# S32K118_M0P register map
Vendor: NXP Semiconductors; File version: 1.1
CPU: CM0PLUS r0p0, little endian, MPU, FPU, VTOR, 4 interrupt priority bits
Registers are 32-bit, read-write, reset 0x0 unless marked. A register's access mark holds for its fields unless they carry their own. Offsets are from the block's base; [hi:lo] are bit positions; {n}, {i} and the like mark numbered series; 'fields as' and 'values as' point back to an identical list.

## TRGMUX
Base 0x40063000
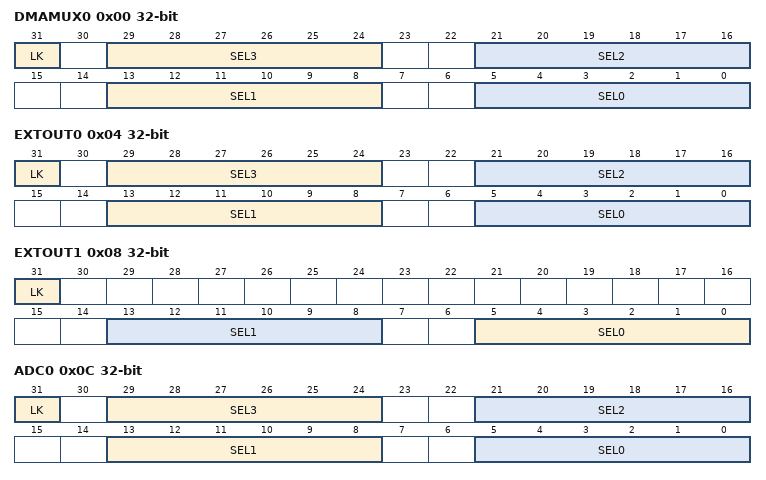
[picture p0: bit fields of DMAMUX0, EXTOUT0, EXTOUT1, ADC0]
0x00 DMAMUX0 — TRGMUX DMAMUX0 Register
  [31] LK — TRGMUX register lock.
    0=UNLOCKED (Register can be written.); 1=LOCKED (Register cannot be written until the next system Reset.)
  [8n+5:8n] SEL{n} (n=0..3) — Trigger MUX Input {n} Source Select
0x04 EXTOUT0 — TRGMUX EXTOUT0 Register
  fields as DMAMUX0
0x08 EXTOUT1 — TRGMUX EXTOUT1 Register
  [31] LK — TRGMUX register lock.
    values as DMAMUX0.LK
  [13:8] SEL1 — Trigger MUX Input 1 Source Select
  [5:0] SEL0 — Trigger MUX Input 0 Source Select
0x0C ADC0 — TRGMUX ADC0 Register
  fields as DMAMUX0
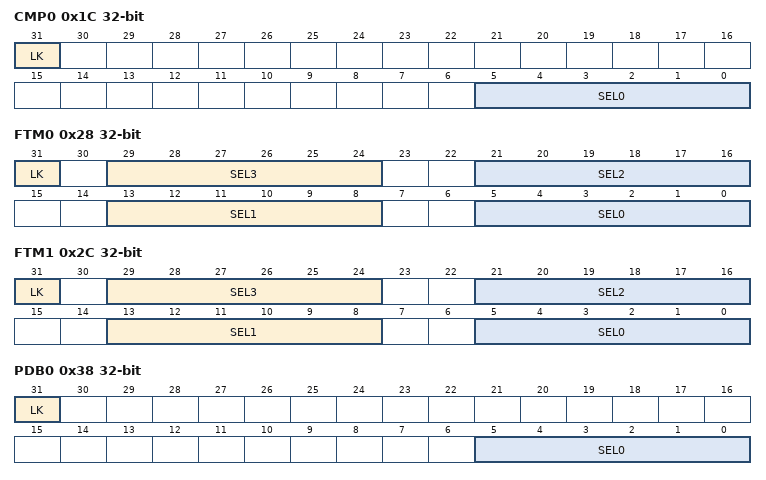
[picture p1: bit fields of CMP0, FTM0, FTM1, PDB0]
0x1C CMP0 — TRGMUX CMP0 Register
  [31] LK — TRGMUX register lock.
    values as DMAMUX0.LK
  [5:0] SEL0 — Trigger MUX Input 0 Source Select
0x28 FTM0 — TRGMUX FTM0 Register
  fields as DMAMUX0
0x2C FTM1 — TRGMUX FTM1 Register
  fields as DMAMUX0
0x38 PDB0 — TRGMUX PDB0 Register
  fields as CMP0
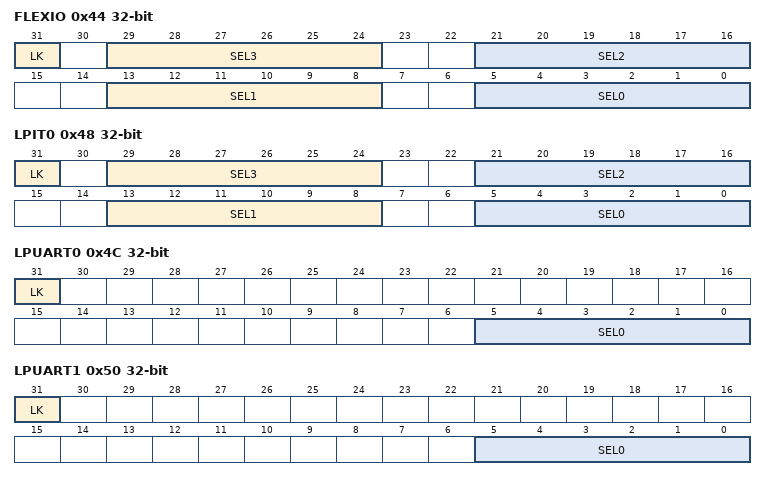
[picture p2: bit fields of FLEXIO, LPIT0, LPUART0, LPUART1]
0x44 FLEXIO — TRGMUX FLEXIO Register
  fields as DMAMUX0
0x48 LPIT0 — TRGMUX LPIT0 Register
  fields as DMAMUX0
0x4C LPUART0 — TRGMUX LPUART0 Register
  fields as CMP0
0x50 LPUART1 — TRGMUX LPUART1 Register
  fields as CMP0
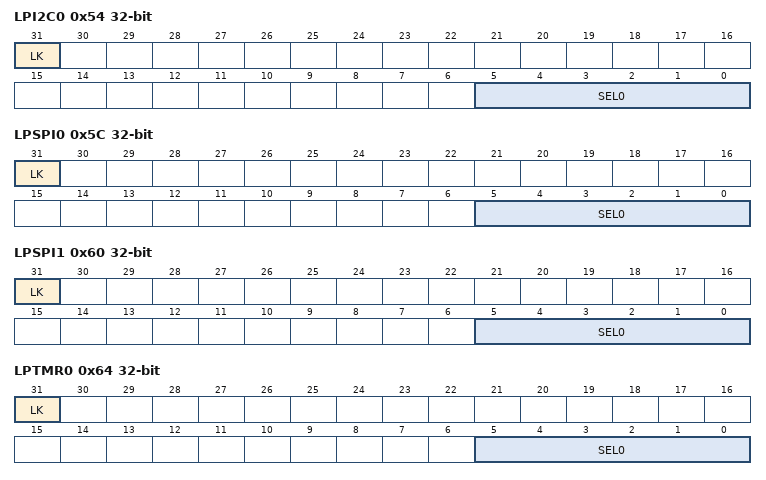
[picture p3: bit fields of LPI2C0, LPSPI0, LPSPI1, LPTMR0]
0x54 LPI2C0 — TRGMUX LPI2C0 Register
  fields as CMP0
0x5C LPSPI0 — TRGMUX LPSPI0 Register
  fields as CMP0
0x60 LPSPI1 — TRGMUX LPSPI1 Register
  fields as CMP0
0x64 LPTMR0 — TRGMUX LPTMR0 Register
  fields as CMP0

## PCC
Base 0x40065000
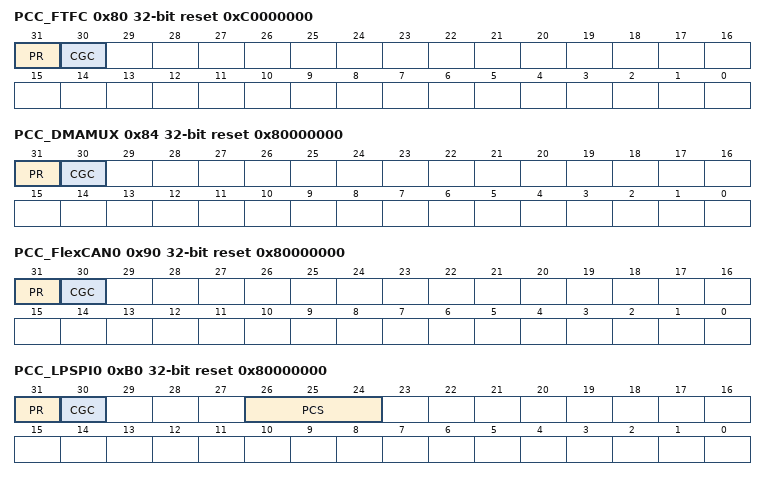
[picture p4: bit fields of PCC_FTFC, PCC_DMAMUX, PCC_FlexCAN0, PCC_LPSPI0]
0x80 PCC_FTFC reset 0xC0000000
  [31] PR ro — Present
    0=NOT_PRESENT (Peripheral is not present.); 1=PRESENT (Peripheral is present.)
  [30] CGC — Clock Gate Control
    0=DISABLED (Clock disabled. The current clock selection and divider options are not locked and can be modified.); 1=ENABLED (Clock enabled. The current clock selection and divider options are locked and cannot be modified.)
0x84 PCC_DMAMUX reset 0x80000000
  fields as PCC_FTFC
0x90 PCC_FlexCAN0 reset 0x80000000
  fields as PCC_FTFC
0xB0 PCC_LPSPI0 reset 0x80000000
  [31] PR ro — Present
    values as PCC_FTFC.PR
  [30] CGC — Clock Gate Control
    values as PCC_FTFC.CGC
  [26:24] PCS — Peripheral Clock Source Select
    0=CLOCK_OFF (Clock is off.); {v}=CLOCK_OPT{v} (Clock option {v}) (v=1..7)
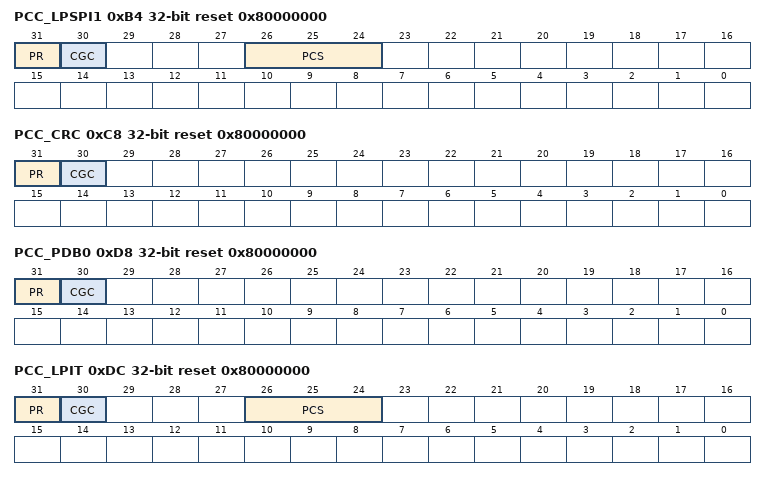
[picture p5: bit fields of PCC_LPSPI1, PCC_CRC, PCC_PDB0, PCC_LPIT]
0xB4 PCC_LPSPI1 reset 0x80000000
  fields as PCC_LPSPI0
0xC8 PCC_CRC reset 0x80000000
  fields as PCC_FTFC
0xD8 PCC_PDB0 reset 0x80000000
  fields as PCC_FTFC
0xDC PCC_LPIT reset 0x80000000
  fields as PCC_LPSPI0
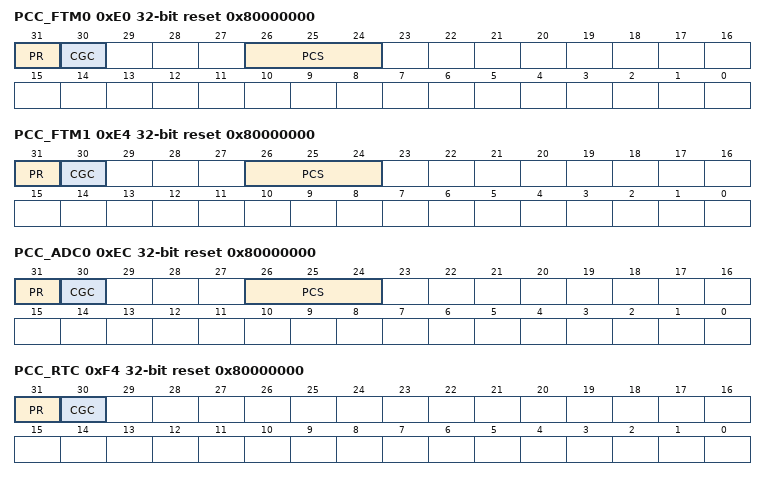
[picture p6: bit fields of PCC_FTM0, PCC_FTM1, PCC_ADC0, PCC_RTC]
0xE0 PCC_FTM0 reset 0x80000000
  [31] PR ro — Present
    values as PCC_FTFC.PR
  [30] CGC — Clock Gate Control
    values as PCC_FTFC.CGC
  [26:24] PCS — Peripheral Clock Source Select
    0=CLOCK_EXT (Clock is off. An external clock can be enabled for this peripheral.); {v}=CLOCK_OPT{v} (Clock option {v}) (v=1..7)
0xE4 PCC_FTM1 reset 0x80000000
  fields as PCC_FTM0
0xEC PCC_ADC0 reset 0x80000000
  fields as PCC_LPSPI0
0xF4 PCC_RTC reset 0x80000000
  fields as PCC_FTFC
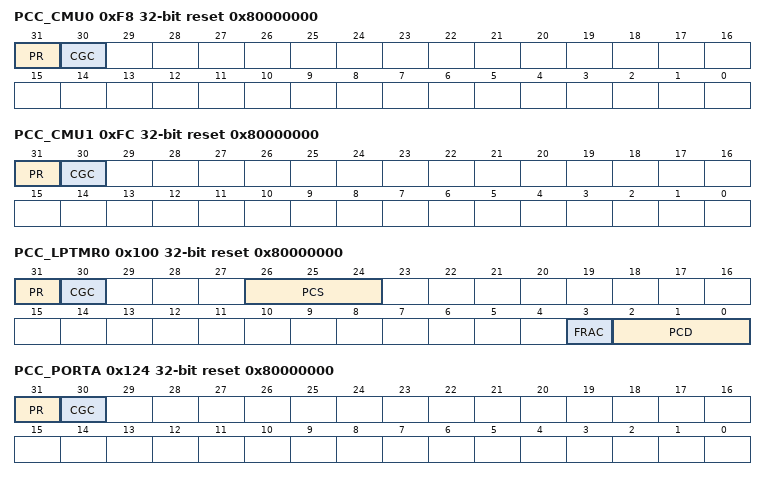
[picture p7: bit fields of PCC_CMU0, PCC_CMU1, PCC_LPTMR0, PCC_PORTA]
0xF8 PCC_CMU0 reset 0x80000000
  fields as PCC_FTFC
0xFC PCC_CMU1 reset 0x80000000
  fields as PCC_FTFC
0x100 PCC_LPTMR0 reset 0x80000000
  [31] PR ro — Present
    values as PCC_FTFC.PR
  [30] CGC — Clock Gate Control
    values as PCC_FTFC.CGC
  [26:24] PCS — Peripheral Clock Source Select
    values as PCC_LPSPI0.PCS
  [3] FRAC — Peripheral Clock Divider Fraction
    0=Fractional value is 0; 1=Fractional value is 1
  [2:0] PCD — Peripheral Clock Divider Select
    {v}=DIV_{v+1} (Divide by {v+1}.) (v=0..7)
0x124 PCC_PORTA reset 0x80000000
  fields as PCC_FTFC
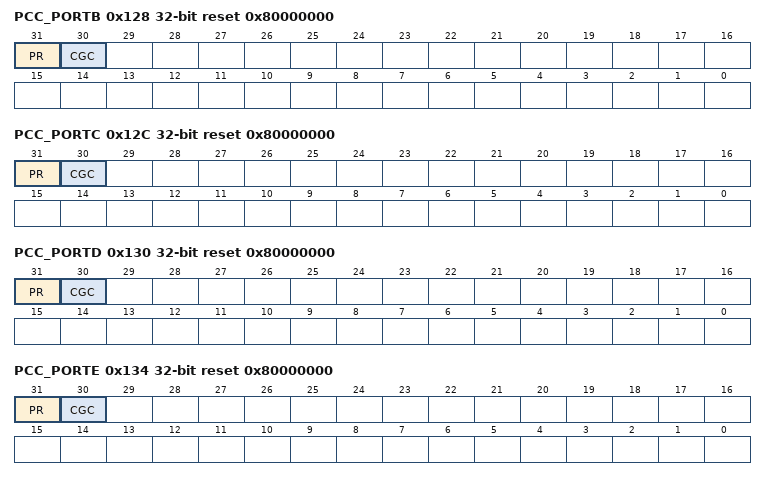
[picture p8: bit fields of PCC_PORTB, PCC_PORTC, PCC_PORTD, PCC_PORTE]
0x128 PCC_PORTB reset 0x80000000
  fields as PCC_FTFC
0x12C PCC_PORTC reset 0x80000000
  fields as PCC_FTFC
0x130 PCC_PORTD reset 0x80000000
  fields as PCC_FTFC
0x134 PCC_PORTE reset 0x80000000
  fields as PCC_FTFC
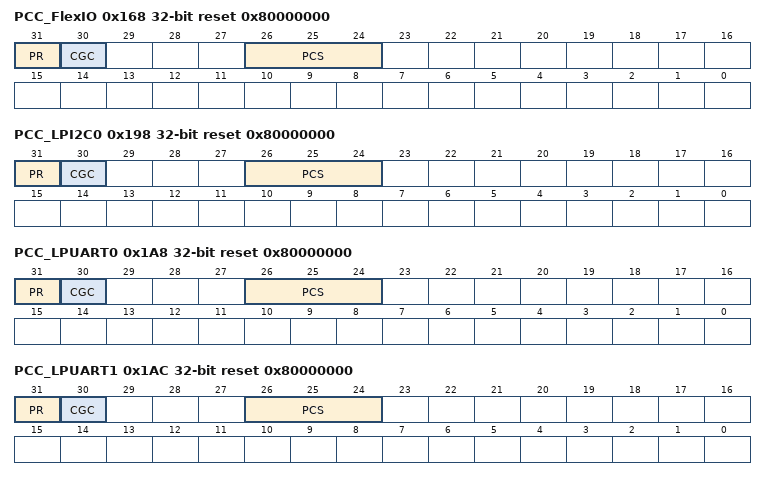
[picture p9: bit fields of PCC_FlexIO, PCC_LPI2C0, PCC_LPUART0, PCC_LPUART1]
0x168 PCC_FlexIO reset 0x80000000
  fields as PCC_LPSPI0
0x198 PCC_LPI2C0 reset 0x80000000
  fields as PCC_LPSPI0
0x1A8 PCC_LPUART0 reset 0x80000000
  fields as PCC_LPSPI0
0x1AC PCC_LPUART1 reset 0x80000000
  fields as PCC_LPSPI0
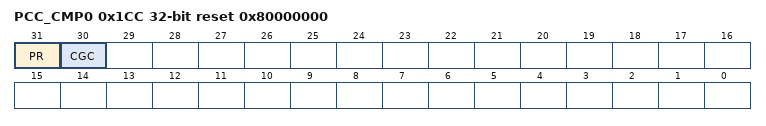
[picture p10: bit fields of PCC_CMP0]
0x1CC PCC_CMP0 reset 0x80000000
  fields as PCC_FTFC
